# EFM32TG11B120F128IQ64 register map
File version: 4.2.0
CPU: CM0PLUS r0p1, little endian, MPU, no FPU, 3 interrupt priority bits
Registers are 32-bit, read-write, reset 0x0 unless marked. A register's access mark holds for its fields unless they carry their own. Offsets are from the block's base; [hi:lo] are bit positions; {n}, {i} and the like mark numbered series; 'fields as' and 'values as' point back to an identical list.

## RTCC
Base 0x40062000
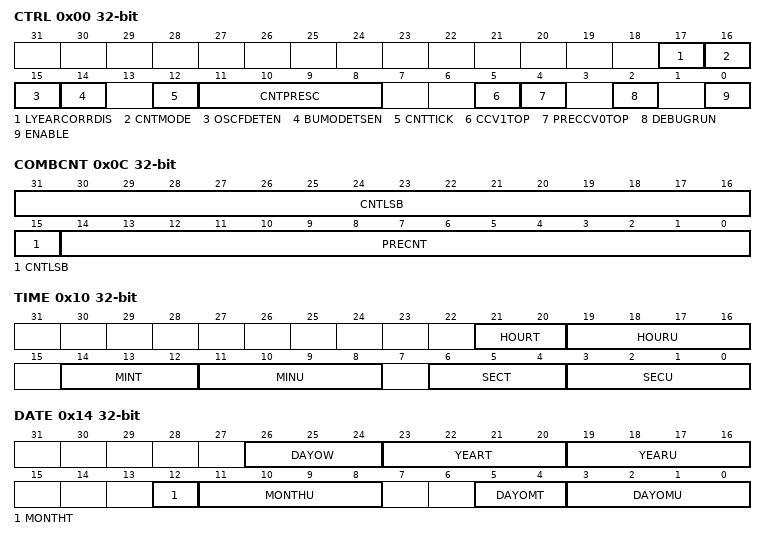
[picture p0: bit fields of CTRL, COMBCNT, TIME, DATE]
0x00 CTRL — Control Register
  [17] LYEARCORRDIS — Leap Year Correction Disabled
  [16] CNTMODE — Main Counter Mode
  [15] OSCFDETEN — Oscillator Failure Detection Enable
  [14] BUMODETSEN — Backup Mode Timestamp Enable
  [12] CNTTICK — Counter Prescaler Mode
  [11:8] CNTPRESC — Counter Prescaler Value
    0=DIV1 (CLKCNT = LFECLKRTCC/1); 1=DIV2 (CLKCNT = LFECLKRTCC/2); 2=DIV4 (CLKCNT = LFECLKRTCC/4); 3=DIV8 (CLKCNT = LFECLKRTCC/8); 4=DIV16 (CLKCNT = LFECLKRTCC/16); 5=DIV32 (CLKCNT = LFECLKRTCC/32); 6=DIV64 (CLKCNT = LFECLKRTCC/64); 7=DIV128 (CLKCNT = LFECLKRTCC/128); 8=DIV256 (CLKCNT = LFECLKRTCC/256); 9=DIV512 (CLKCNT = LFECLKRTCC/512); 10=DIV1024 (CLKCNT = LFECLKRTCC/1024); 11=DIV2048 (CLKCNT = LFECLKRTCC/2048); 12=DIV4096 (CLKCNT = LFECLKRTCC/4096); 13=DIV8192 (CLKCNT = LFECLKRTCC/8192); 14=DIV16384 (CLKCNT = LFECLKRTCC/16384); 15=DIV32768 (CLKCNT = LFECLKRTCC/32768)
  [5] CCV1TOP — CCV1 Top Value Enable
  [4] PRECCV0TOP — Pre-counter CCV0 Top Value Enable
  [2] DEBUGRUN — Debug Mode Run Enable
  [0] ENABLE — RTCC Enable
0x04 PRECNT — Pre-Counter Value Register
  [14:0] PRECNT — Pre-Counter Value
0x08 CNT — Counter Value Register
  [31:0] CNT — Counter Value
0x0C COMBCNT ro — Combined Pre-Counter and Counter Value Register
  [31:15] CNTLSB — Counter Value
  [14:0] PRECNT — Pre-Counter Value
0x10 TIME — Time of Day Register
  [21:20] HOURT — Hours, Tens
  [19:16] HOURU — Hours, Units
  [14:12] MINT — Minutes, Tens
  [11:8] MINU — Minutes, Units
  [6:4] SECT — Seconds, Tens
  [3:0] SECU — Seconds, Units
0x14 DATE
  [26:24] DAYOW — Day of Week
  [23:20] YEART — Year, Tens
  [19:16] YEARU — Year, Units
  [12] MONTHT — Month, Tens
  [11:8] MONTHU — Month, Units
  [5:4] DAYOMT — Day of Month, Tens
  [3:0] DAYOMU — Day of Month, Units
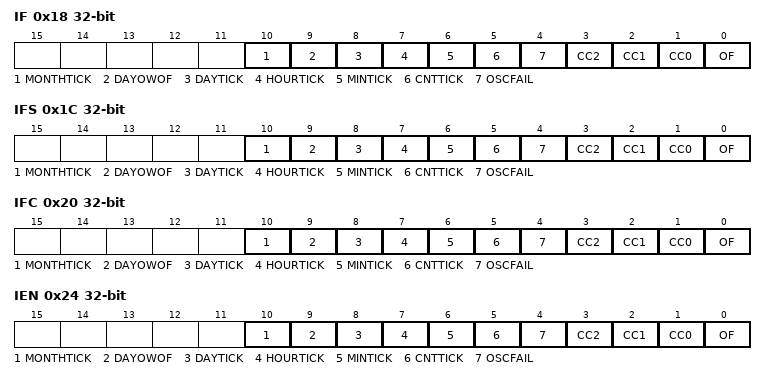
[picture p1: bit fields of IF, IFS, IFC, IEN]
0x18 IF ro — RTCC Interrupt Flags
  [10] MONTHTICK
  [9] DAYOWOF — Day of Week Overflow
  [8] DAYTICK
  [7] HOURTICK
  [6] MINTICK — Minute Tick
  [5] CNTTICK — Main Counter Tick
  [4] OSCFAIL — Oscillator Failure Interrupt Flag
  [3] CC2 — Channel 2 Interrupt Flag
  [2] CC1 — Channel 1 Interrupt Flag
  [1] CC0 — Channel 0 Interrupt Flag
  [0] OF — Overflow Interrupt Flag
0x1C IFS wo — Interrupt Flag Set Register
  [10] MONTHTICK — Set MONTHTICK Interrupt Flag
  [9] DAYOWOF — Set DAYOWOF Interrupt Flag
  [8] DAYTICK — Set DAYTICK Interrupt Flag
  [7] HOURTICK — Set HOURTICK Interrupt Flag
  [6] MINTICK — Set MINTICK Interrupt Flag
  [5] CNTTICK — Set CNTTICK Interrupt Flag
  [4] OSCFAIL — Set OSCFAIL Interrupt Flag
  [3] CC2 — Set CC2 Interrupt Flag
  [2] CC1 — Set CC1 Interrupt Flag
  [1] CC0 — Set CC0 Interrupt Flag
  [0] OF — Set OF Interrupt Flag
0x20 IFC wo — Interrupt Flag Clear Register
  [10] MONTHTICK — Clear MONTHTICK Interrupt Flag
  [9] DAYOWOF — Clear DAYOWOF Interrupt Flag
  [8] DAYTICK — Clear DAYTICK Interrupt Flag
  [7] HOURTICK — Clear HOURTICK Interrupt Flag
  [6] MINTICK — Clear MINTICK Interrupt Flag
  [5] CNTTICK — Clear CNTTICK Interrupt Flag
  [4] OSCFAIL — Clear OSCFAIL Interrupt Flag
  [3] CC2 — Clear CC2 Interrupt Flag
  [2] CC1 — Clear CC1 Interrupt Flag
  [1] CC0 — Clear CC0 Interrupt Flag
  [0] OF — Clear OF Interrupt Flag
0x24 IEN — Interrupt Enable Register
  [10] MONTHTICK — MONTHTICK Interrupt Enable
  [9] DAYOWOF — DAYOWOF Interrupt Enable
  [8] DAYTICK — DAYTICK Interrupt Enable
  [7] HOURTICK — HOURTICK Interrupt Enable
  [6] MINTICK — MINTICK Interrupt Enable
  [5] CNTTICK — CNTTICK Interrupt Enable
  [4] OSCFAIL — OSCFAIL Interrupt Enable
  [3] CC2 — CC2 Interrupt Enable
  [2] CC1 — CC1 Interrupt Enable
  [1] CC0 — CC0 Interrupt Enable
  [0] OF — OF Interrupt Enable
0x28 STATUS ro
  [0] BUMODETS — Timestamp for Backup Mode Entry Stored
0x2C CMD wo — Command Register
  [0] CLRSTATUS — Clear RTCC_STATUS Register
0x30 SYNCBUSY ro — Synchronization Busy Register
  [5] CMD — CMD Register Busy
0x34 POWERDOWN — Retention RAM Power-down Register
  [0] RAM — Retention RAM Power-down
0x38 LOCK — Configuration Lock Register
  [15:0] LOCKKEY — Configuration Lock Key
    0=UNLOCKED; 1=LOCKED
0x3C EM4WUEN — Wake Up Enable
  [0] EM4WU — EM4 Wake-up Enable
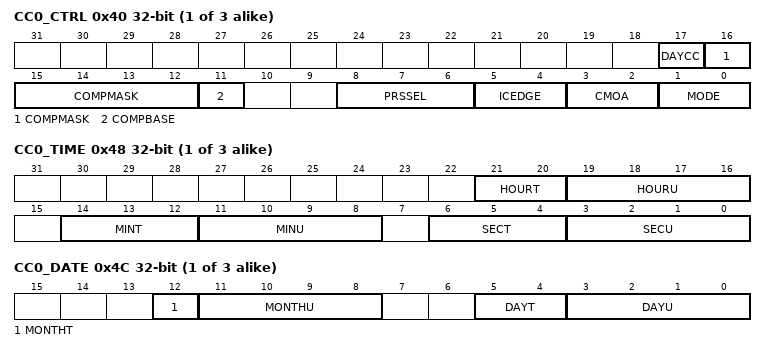
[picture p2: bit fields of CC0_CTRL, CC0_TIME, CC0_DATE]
{0x40+0x10*i} CC{i}_CTRL (i=0..2) — CC Channel Control Register
  [17] DAYCC — Day Capture/Compare Selection
  [16:12] COMPMASK — Capture Compare Channel Comparison Mask
  [11] COMPBASE — Capture Compare Channel Comparison Base
  [8:6] PRSSEL — Compare/Capture Channel PRS Input Channel Selection
    {v}=PRSCH{v} (PRS Channel {v} selected as input) (v=0..7)
  [5:4] ICEDGE — Input Capture Edge Select
    0=RISING (Rising edges detected); 1=FALLING (Falling edges detected); 2=BOTH (Both edges detected); 3=NONE (No edge detection, signal is left as it is)
  [3:2] CMOA — Compare Match Output Action
    0=PULSE (A single clock cycle pulse is generated on output); 1=TOGGLE (Toggle output on compare match); 2=CLEAR (Clear output on compare match); 3=SET (Set output on compare match)
  [1:0] MODE — CC Channel Mode
    0=OFF (Compare/Capture channel turned off); 1=INPUTCAPTURE; 2=OUTPUTCOMPARE
{0x44+0x10*i} CC{i}_CCV (i=0..2) — Capture/Compare Value Register
  [31:0] CCV — Capture/Compare Value
{0x48+0x10*i} CC{i}_TIME (i=0..2) — Capture/Compare Time Register
  fields as TIME
{0x4C+0x10*i} CC{i}_DATE (i=0..2) — Capture/Compare Date Register
  [12] MONTHT — Month, Tens
  [11:8] MONTHU — Month, Units
  [5:4] DAYT — Day of Month/week, Tens
  [3:0] DAYU — Day of Month/week, Units
{0x104+4i} RET{i}_REG (i=0..31) — Retention Register
  [31:0] REG — General Purpose Retention Register

## Notices in the file
# License
Copyright 2022 Silicon Laboratories Inc. www.silabs.com
SPDX-License-Identifier: Zlib
The licensor of this software is Silicon Laboratories Inc.
This software is provided 'as-is', without any express or implied
warranty. In no event will the authors be held liable for any damages
arising from the use of this software.
Permission is granted to anyone to use this software for any purpose,
including commercial applications, and to alter it and redistribute it
freely, subject to the following restrictions:
1. The origin of this software must not be misrepresented; you must not
claim that you wrote the original software. If you use this software
in a product, an acknowledgment in the product documentation would be
appreciated but is not required.
2. Altered source versions must be plainly marked as such, and must not be
misrepresented as being the original software.
3. This notice may not be removed or altered from any source distribution.
